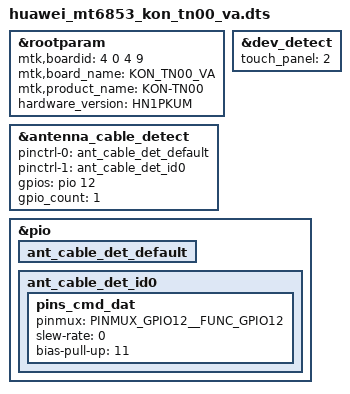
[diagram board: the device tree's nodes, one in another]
#include <dt-bindings/interrupt-controller/arm-gic.h>
#include <dt-bindings/interrupt-controller/irq.h>
#include <dt-bindings/pinctrl/mt6853-pinfunc.h>
/dts-v1/;
/plugin/;

#include "huawei_mt6853_kon_tn00_va/huawei.dtsi"

&rootparam {
    mtk,boardid = <4 0 4 9>;
    mtk,board_name = "KON_TN00_VA";
    mtk,product_name = "KON-TN00";
    hardware_version = "HN1PKUM";
};

&dev_detect{
    touch_panel = <2>;
    status = "ok";
};

&antenna_cable_detect {
	pinctrl-names = "default", "id0";
	pinctrl-0 = <&ant_cable_det_default>;
	pinctrl-1 = <&ant_cable_det_id0>;
	gpios = <&pio 12 0 >;
	gpio_count = <1>;
};

&pio {
	ant_cable_det_default: ant_cable_det_default {
	};

	ant_cable_det_id0: ant_cable_det_id0 {
		pins_cmd_dat {
			pinmux = <PINMUX_GPIO12__FUNC_GPIO12>;
			slew-rate = <0>;
			bias-pull-up = <11>;
		};
	};
};
#include <k6853v1_64/cust.dtsi>

/*End of this file, DO NOT ADD ANYTHING HERE*/
